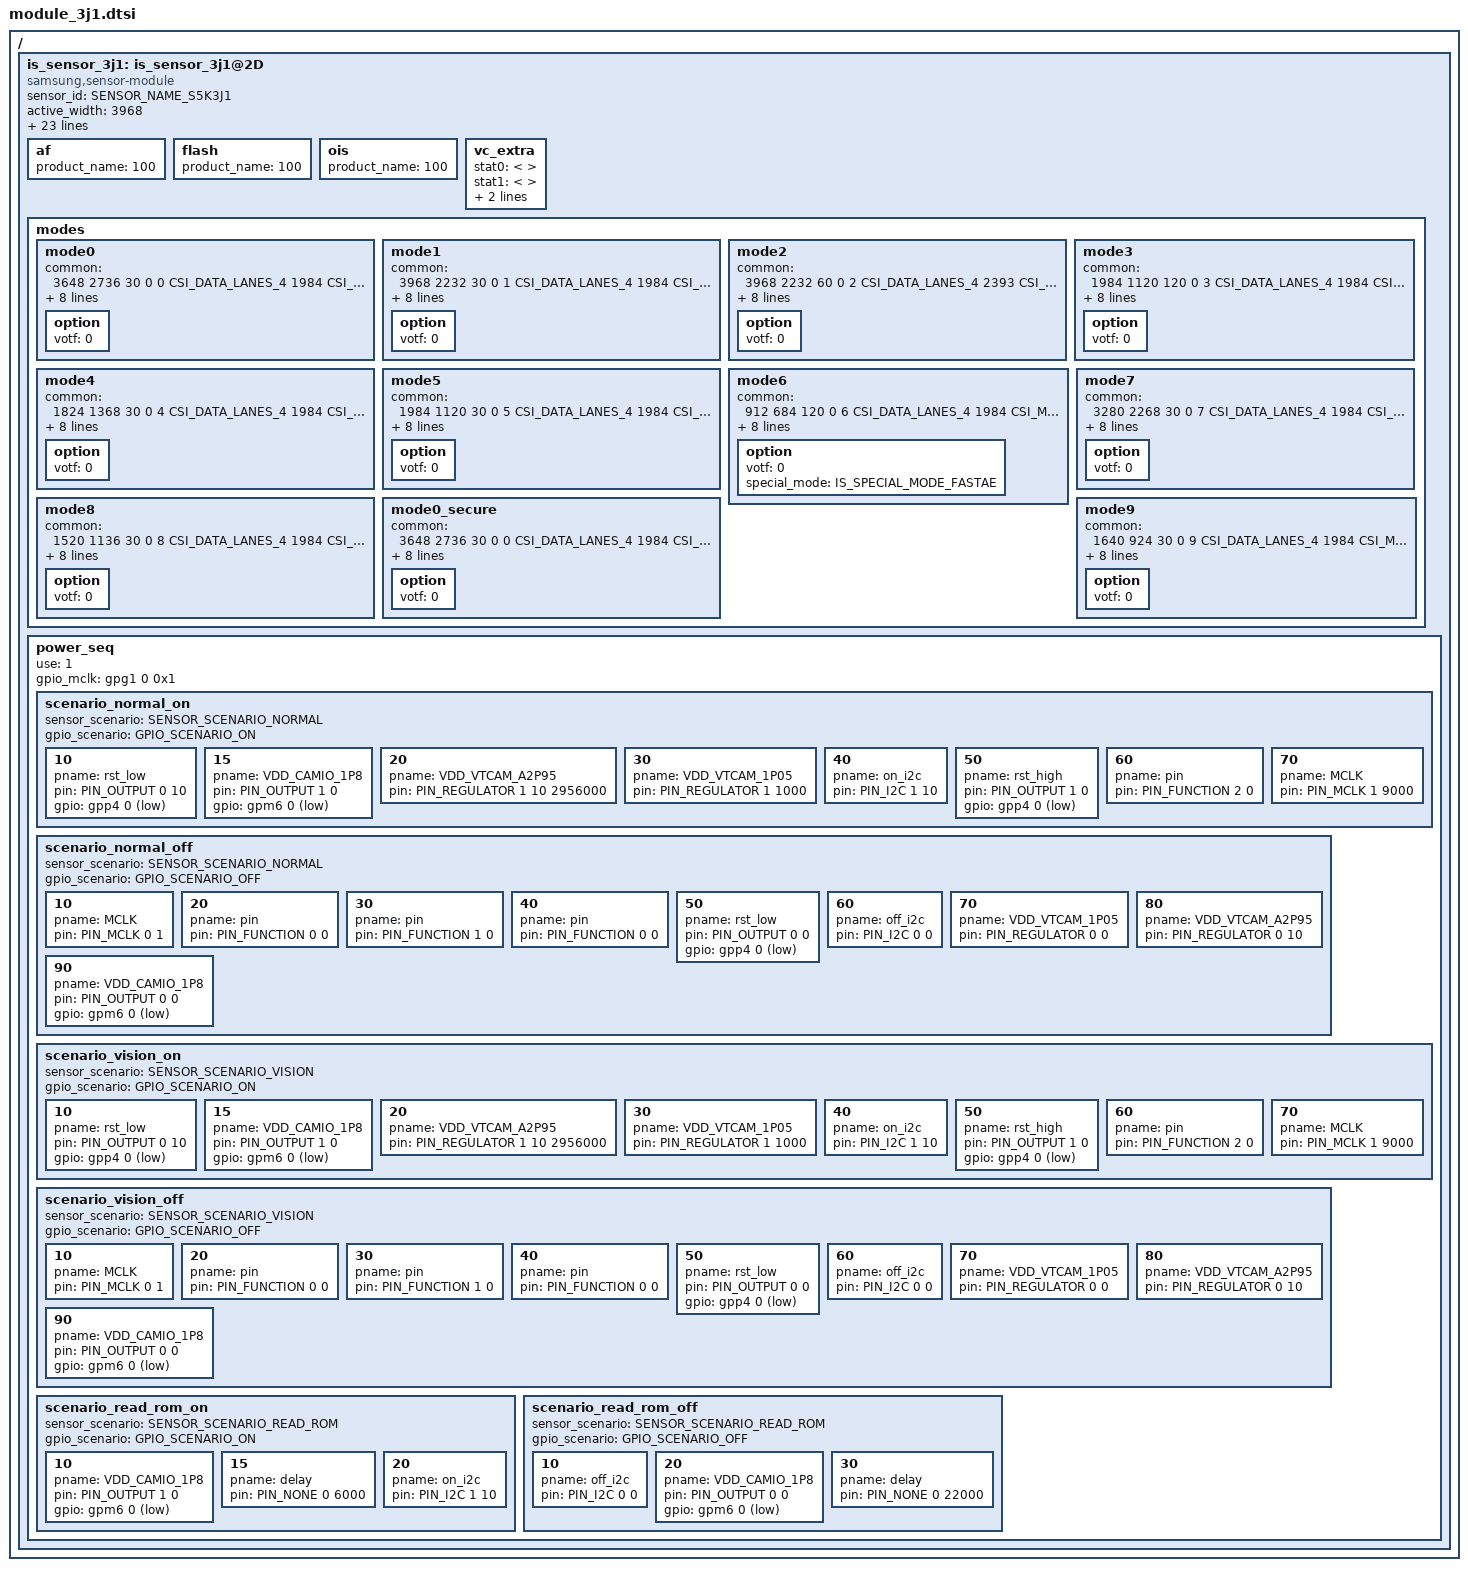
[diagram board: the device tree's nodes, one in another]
/*
 * SAMSUNG EXYNOSxxxx board camera device tree source
 *
 * Copyright (c) 2024 Samsung Electronics Co., Ltd.
 *		http://www.samsung.com
 *
 * This program is free software; you can redistribute it and/or modify
 * it under the terms of the GNU General Public License version 2 as
 * published by the Free Software Foundation.
 */

#include <dt-bindings/camera/exynos_is_dt.h>

/ {
	fragment@camera {
		target-path = "/";
		__overlay__ {
			is_sensor_3j1: is_sensor_3j1@2D {
				compatible = "samsung,sensor-module";

				/* common */
				sensor_id = <SENSOR_NAME_S5K3J1>;
				active_width = <3968>;
				active_height = <2736>;
				margin_left = <0>;
				margin_right = <0>;
				margin_top = <0>;
				margin_bottom = <0>;
				max_framerate = <120>;
				bitwidth = <10>;
				use_retention_mode = <SENSOR_RETENTION_UNSUPPORTED>;
				sensor_maker = "SLSI";
				sensor_name = "S5K3J1";
				setfile_name = "setfile_3j1.bin";

				status = "okay";

				/* board */
				pinctrl-names = "pin0", "pin1", "pin2", "release";
				pinctrl-0 = <>;
				pinctrl-1 = <&sensor_mclk0_out>;
				pinctrl-2 = <&sensor_mclk0_fn>;
				pinctrl-3 = <>;

				position = <1>;	/* Rear:0. Front:1. Rear_sub:2. Secure:3. */
				id = <1>; /* is_sensor id */
				mclk_ch = <0>;
				mclk_freq = <19200>;
				sensor_i2c_ch = <5>; /* SENSOR_CONTROL_I2C5 */

				/* vendor */
				rom_id = <1>;
				rom_cal_index = <0>;

				/* peri*/
				af {
					product_name = <100>; /* NOTHING */
				};

				flash {
					product_name = <100>; /* NOTHING */
				};

				ois {
					product_name = <100>; /* NOTHING */
				};

				vc_extra {
					/* ex) statX = <stat_type, sensor_mode, max_width, max_height, max_element> */
					stat0 = </* not available */>;		/* VC_BUF_DATA_TYPE_SENSOR_STAT1 */
					stat1 = </* not available */>;		/* VC_BUF_DATA_TYPE_GENERAL_STAT1 */
					stat2 = </* not available */>;		/* VC_BUF_DATA_TYPE_SENSOR_STAT2 */
					stat3 = </* not available */>;		/* VC_BUF_DATA_TYPE_GENERAL_STAT2 */
				};

				/* sensor modes */
				modes {
					/* mode0 : 3648x2736@30 (4:3) */
					/* mode1 : 3968x2232@30 (16:9) */
					/* mode2 : 3968x2232@60 (16:9) */
					/* mode3 : 1984x1120@120 2x2 bin (16:9) */
					/* mode4 : 1824x1368@30 2x2 bin (4:3) */
					/* mode5 : 1984x1120@30 2x2 bin (16:9) */
					/* mode6 : 912x684@120 4x4 bin (4:3) */

						/* common = <width, height, fps, settle, mode, lane, speed, interleave, lrte, pd_mode> */
						/* vcX = <map, hwformat, width, height, hwformat, type, width, height> */
					mode0 {
						common = <3648 2736 30 0 0 CSI_DATA_LANES_4 1984 CSI_MODE_VC_ONLY LRTE_DISABLE PD_NONE EX_NONE>;
						vc0 = </* in */ 0 HW_FORMAT_RAW10 DATA_IMG 3648 2736	/* out */ HW_FORMAT_RAW10 VC_NOTHING 3648 2736>;
						vc1 = </* in */ 1 HW_FORMAT_UNKNOWN DATA_NONE 0 0	/* out */ HW_FORMAT_UNKNOWN VC_NOTHING 0 0>;
						vc2 = </* in */ 2 HW_FORMAT_UNKNOWN DATA_NONE 0 0	/* out */ HW_FORMAT_UNKNOWN VC_NOTHING 0 0>;
						vc3 = </* in */ 3 HW_FORMAT_UNKNOWN DATA_NONE 0 0	/* out */ HW_FORMAT_UNKNOWN VC_NOTHING 0 0>;
						option { votf = <0>; };
					};
					mode1 {
						common = <3968 2232 30 0 1 CSI_DATA_LANES_4 1984 CSI_MODE_VC_ONLY LRTE_DISABLE PD_NONE EX_NONE>;
						vc0 = </* in */ 0 HW_FORMAT_RAW10 DATA_IMG 3968 2232	/* out */ HW_FORMAT_RAW10 VC_NOTHING 3968 2232>;
						vc1 = </* in */ 1 HW_FORMAT_UNKNOWN DATA_NONE 0 0	/* out */ HW_FORMAT_UNKNOWN VC_NOTHING 0 0>;
						vc2 = </* in */ 2 HW_FORMAT_UNKNOWN DATA_NONE 0 0	/* out */ HW_FORMAT_UNKNOWN VC_NOTHING 0 0>;
						vc3 = </* in */ 3 HW_FORMAT_UNKNOWN DATA_NONE 0 0	/* out */ HW_FORMAT_UNKNOWN VC_NOTHING 0 0>;
						option { votf = <0>; };
					};
					mode2 {
						common = <3968 2232 60 0 2 CSI_DATA_LANES_4 2393 CSI_MODE_VC_ONLY LRTE_DISABLE PD_NONE EX_NONE>;
						vc0 = </* in */ 0 HW_FORMAT_RAW10 DATA_IMG 3968 2232	/* out */ HW_FORMAT_RAW10 VC_NOTHING 3968 2232>;
						vc1 = </* in */ 1 HW_FORMAT_UNKNOWN DATA_NONE 0 0	/* out */ HW_FORMAT_UNKNOWN VC_NOTHING 0 0>;
						vc2 = </* in */ 2 HW_FORMAT_UNKNOWN DATA_NONE 0 0	/* out */ HW_FORMAT_UNKNOWN VC_NOTHING 0 0>;
						vc3 = </* in */ 3 HW_FORMAT_UNKNOWN DATA_NONE 0 0	/* out */ HW_FORMAT_UNKNOWN VC_NOTHING 0 0>;
						option { votf = <0>; };
					};
					mode3 {
						common = <1984 1120 120 0 3 CSI_DATA_LANES_4 1984 CSI_MODE_VC_ONLY LRTE_DISABLE PD_NONE EX_NONE>;
						vc0 = </* in */ 0 HW_FORMAT_RAW10 DATA_IMG 1984 1120	/* out */ HW_FORMAT_RAW10 VC_NOTHING 1984 1120>;
						vc1 = </* in */ 1 HW_FORMAT_UNKNOWN DATA_NONE 0 0	/* out */ HW_FORMAT_UNKNOWN VC_NOTHING 0 0>;
						vc2 = </* in */ 2 HW_FORMAT_UNKNOWN DATA_NONE 0 0	/* out */ HW_FORMAT_UNKNOWN VC_NOTHING 0 0>;
						vc3 = </* in */ 3 HW_FORMAT_UNKNOWN DATA_NONE 0 0	/* out */ HW_FORMAT_UNKNOWN VC_NOTHING 0 0>;
						option { votf = <0>; };
					};
					mode4 {
						common = <1824 1368 30 0 4 CSI_DATA_LANES_4 1984 CSI_MODE_VC_ONLY LRTE_DISABLE PD_NONE EX_NONE>;
						vc0 = </* in */ 0 HW_FORMAT_RAW10 DATA_IMG 1824 1368	/* out */ HW_FORMAT_RAW10 VC_NOTHING 1824 1368>;
						vc1 = </* in */ 1 HW_FORMAT_UNKNOWN DATA_NONE 0 0	/* out */ HW_FORMAT_UNKNOWN VC_NOTHING 0 0>;
						vc2 = </* in */ 2 HW_FORMAT_UNKNOWN DATA_NONE 0 0	/* out */ HW_FORMAT_UNKNOWN VC_NOTHING 0 0>;
						vc3 = </* in */ 3 HW_FORMAT_UNKNOWN DATA_NONE 0 0	/* out */ HW_FORMAT_UNKNOWN VC_NOTHING 0 0>;
						option { votf = <0>; };
					};
					mode5 {
						common = <1984 1120 30 0 5 CSI_DATA_LANES_4 1984 CSI_MODE_VC_ONLY LRTE_DISABLE PD_NONE EX_NONE>;
						vc0 = </* in */ 0 HW_FORMAT_RAW10 DATA_IMG 1984 1120	/* out */ HW_FORMAT_RAW10 VC_NOTHING 1984 1120>;
						vc1 = </* in */ 1 HW_FORMAT_UNKNOWN DATA_NONE 0 0	/* out */ HW_FORMAT_UNKNOWN VC_NOTHING 0 0>;
						vc2 = </* in */ 2 HW_FORMAT_UNKNOWN DATA_NONE 0 0	/* out */ HW_FORMAT_UNKNOWN VC_NOTHING 0 0>;
						vc3 = </* in */ 3 HW_FORMAT_UNKNOWN DATA_NONE 0 0	/* out */ HW_FORMAT_UNKNOWN VC_NOTHING 0 0>;
						option { votf = <0>; };
					};
					mode6 {
						common = <912 684 120 0 6 CSI_DATA_LANES_4 1984 CSI_MODE_VC_ONLY LRTE_DISABLE PD_NONE EX_NONE>;
						vc0 = </* in */ 0 HW_FORMAT_RAW10 DATA_IMG 912 684	/* out */ HW_FORMAT_RAW10 VC_NOTHING 912 684>;
						vc1 = </* in */ 1 HW_FORMAT_UNKNOWN DATA_NONE 0 0	/* out */ HW_FORMAT_UNKNOWN VC_NOTHING 0 0>;
						vc2 = </* in */ 2 HW_FORMAT_UNKNOWN DATA_NONE 0 0	/* out */ HW_FORMAT_UNKNOWN VC_NOTHING 0 0>;
						vc3 = </* in */ 3 HW_FORMAT_UNKNOWN DATA_NONE 0 0	/* out */ HW_FORMAT_UNKNOWN VC_NOTHING 0 0>;
						option { votf = <0>; special_mode = <IS_SPECIAL_MODE_FASTAE>; };
					};
					mode7 {
						common = <3280 2268 30 0 7 CSI_DATA_LANES_4 1984 CSI_MODE_VC_ONLY LRTE_DISABLE PD_NONE EX_NONE>;
						vc0 = </* in */ 0 HW_FORMAT_RAW10 DATA_IMG 3280 2268	/* out */ HW_FORMAT_RAW10 VC_NOTHING 3280 2268>;
						vc1 = </* in */ 1 HW_FORMAT_UNKNOWN DATA_NONE 0 0	/* out */ HW_FORMAT_UNKNOWN VC_NOTHING 0 0>;
						vc2 = </* in */ 2 HW_FORMAT_UNKNOWN DATA_NONE 0 0	/* out */ HW_FORMAT_UNKNOWN VC_NOTHING 0 0>;
						vc3 = </* in */ 3 HW_FORMAT_UNKNOWN DATA_NONE 0 0	/* out */ HW_FORMAT_UNKNOWN VC_NOTHING 0 0>;
						option { votf = <0>; };
					};
					mode8 {
						common = <1520 1136 30 0 8 CSI_DATA_LANES_4 1984 CSI_MODE_VC_ONLY LRTE_DISABLE PD_NONE EX_NONE>;
						vc0 = </* in */ 0 HW_FORMAT_RAW10 DATA_IMG 1520 1136	/* out */ HW_FORMAT_RAW10 VC_NOTHING 1520 1136>;
						vc1 = </* in */ 1 HW_FORMAT_UNKNOWN DATA_NONE 0 0	/* out */ HW_FORMAT_UNKNOWN VC_NOTHING 0 0>;
						vc2 = </* in */ 2 HW_FORMAT_UNKNOWN DATA_NONE 0 0	/* out */ HW_FORMAT_UNKNOWN VC_NOTHING 0 0>;
						vc3 = </* in */ 3 HW_FORMAT_UNKNOWN DATA_NONE 0 0	/* out */ HW_FORMAT_UNKNOWN VC_NOTHING 0 0>;
						option { votf = <0>; };
					};
					mode9 {
						common = <1640 924 30 0 9 CSI_DATA_LANES_4 1984 CSI_MODE_VC_ONLY LRTE_DISABLE PD_NONE EX_NONE>;
						vc0 = </* in */ 0 HW_FORMAT_RAW10 DATA_IMG 1640 924	/* out */ HW_FORMAT_RAW10 VC_NOTHING 1640 924>;
						vc1 = </* in */ 1 HW_FORMAT_UNKNOWN DATA_NONE 0 0	/* out */ HW_FORMAT_UNKNOWN VC_NOTHING 0 0>;
						vc2 = </* in */ 2 HW_FORMAT_UNKNOWN DATA_NONE 0 0	/* out */ HW_FORMAT_UNKNOWN VC_NOTHING 0 0>;
						vc3 = </* in */ 3 HW_FORMAT_UNKNOWN DATA_NONE 0 0	/* out */ HW_FORMAT_UNKNOWN VC_NOTHING 0 0>;
						option { votf = <0>; };
					};
					/* For SECURE CAMERA FD Scenario */
					mode0_secure {
						common = <3648 2736 30 0 0 CSI_DATA_LANES_4 1984 CSI_MODE_VC_ONLY LRTE_DISABLE PD_NONE EX_PDAF_OFF>;
						vc0 = </* in */ 0 HW_FORMAT_RAW10 DATA_IMG 3648 2736	/* out */ HW_FORMAT_RAW10 VC_NOTHING 1824 1368>;
						vc1 = </* in */ 1 HW_FORMAT_UNKNOWN DATA_NONE 0 0	/* out */ HW_FORMAT_UNKNOWN VC_NOTHING 0 0>;
						vc2 = </* in */ 2 HW_FORMAT_UNKNOWN DATA_NONE 0 0	/* out */ HW_FORMAT_UNKNOWN VC_NOTHING 0 0>;
						vc3 = </* in */ 3 HW_FORMAT_UNKNOWN DATA_NONE 0 0	/* out */ HW_FORMAT_UNKNOWN VC_NOTHING 0 0>;
						option { votf = <0>; };
					};
				};

				power_seq {
					use = <1>;
					gpio_mclk = <&gpg1 0 0x1>;
					scenario_normal_on {
						sensor_scenario = <SENSOR_SCENARIO_NORMAL>;
						gpio_scenario = <GPIO_SCENARIO_ON>;

						/* A start node number should be over the 10 for reserved number 0~9. */
						/* pname = "name"; pin = <act value delay voltage>; gpio = <gpx# # 0x1>; */
						10 { pname = "rst_low"; pin = <PIN_OUTPUT 0 10>; gpio = <&gpp4 0 0x1>; };
						15 { pname = "VDD_CAMIO_1P8"; pin = <PIN_OUTPUT 1 0>; gpio = <&gpm6 0 0x1>; };
						20 { pname = "VDD_VTCAM_A2P95"; pin = <PIN_REGULATOR 1 10 2956000>; };
						30 { pname = "VDD_VTCAM_1P05"; pin = <PIN_REGULATOR 1 1000>; };
						40 { pname = "on_i2c"; pin = <PIN_I2C 1 10>; };
						50 { pname = "rst_high"; pin = <PIN_OUTPUT 1 0>; gpio = <&gpp4 0 0x1>; };
						60 { pname = "pin"; pin = <PIN_FUNCTION 2 0>; };
						70 { pname = "MCLK"; pin = <PIN_MCLK 1 9000>; };
					};

					scenario_normal_off {
						sensor_scenario = <SENSOR_SCENARIO_NORMAL>;
						gpio_scenario = <GPIO_SCENARIO_OFF>;

						/* A start node number should be over the 10 for reserved number 0~9. */
						/* pname = "name"; pin = <act value delay voltage>; gpio = <gpx# # 0x1>; */
						10 { pname = "MCLK"; pin = <PIN_MCLK 0 1>; };
						20 { pname = "pin"; pin = <PIN_FUNCTION 0 0>; };
						30 { pname = "pin"; pin = <PIN_FUNCTION 1 0>; };
						40 { pname = "pin"; pin = <PIN_FUNCTION 0 0>; };
						50 { pname = "rst_low"; pin = <PIN_OUTPUT 0 0>; gpio = <&gpp4 0 0x1>; };
						60 { pname = "off_i2c"; pin = <PIN_I2C 0 0>; };
						70 { pname = "VDD_VTCAM_1P05"; pin = <PIN_REGULATOR 0 0>; };
						80 { pname = "VDD_VTCAM_A2P95"; pin = <PIN_REGULATOR 0 10>; };
						90 { pname = "VDD_CAMIO_1P8"; pin = <PIN_OUTPUT 0 0>; gpio = <&gpm6 0 0x1>; };
					};

					scenario_vision_on {
						sensor_scenario = <SENSOR_SCENARIO_VISION>;
						gpio_scenario = <GPIO_SCENARIO_ON>;

						/* A start node number should be over the 10 for reserved number 0~9. */
						/* pname = "name"; pin = <act value delay voltage>; gpio = <gpx# # 0x1>; */
						10 { pname = "rst_low"; pin = <PIN_OUTPUT 0 10>; gpio = <&gpp4 0 0x1>; };
						15 { pname = "VDD_CAMIO_1P8"; pin = <PIN_OUTPUT 1 0>; gpio = <&gpm6 0 0x1>; };
						20 { pname = "VDD_VTCAM_A2P95"; pin = <PIN_REGULATOR 1 10 2956000>; };
						30 { pname = "VDD_VTCAM_1P05"; pin = <PIN_REGULATOR 1 1000>; };
						40 { pname = "on_i2c"; pin = <PIN_I2C 1 10>; };
						50 { pname = "rst_high"; pin = <PIN_OUTPUT 1 0>; gpio = <&gpp4 0 0x1>; };
						60 { pname = "pin"; pin = <PIN_FUNCTION 2 0>; };
						70 { pname = "MCLK"; pin = <PIN_MCLK 1 9000>; };
					};

					scenario_vision_off {
						sensor_scenario = <SENSOR_SCENARIO_VISION>;
						gpio_scenario = <GPIO_SCENARIO_OFF>;

						/* A start node number should be over the 10 for reserved number 0~9. */
						/* pname = "name"; pin = <act value delay voltage>; gpio = <gpx# # 0x1>; */
						10 { pname = "MCLK"; pin = <PIN_MCLK 0 1>; };
						20 { pname = "pin"; pin = <PIN_FUNCTION 0 0>; };
						30 { pname = "pin"; pin = <PIN_FUNCTION 1 0>; };
						40 { pname = "pin"; pin = <PIN_FUNCTION 0 0>; };
						50 { pname = "rst_low"; pin = <PIN_OUTPUT 0 0>; gpio = <&gpp4 0 0x1>; };
						60 { pname = "off_i2c"; pin = <PIN_I2C 0 0>; };
						70 { pname = "VDD_VTCAM_1P05"; pin = <PIN_REGULATOR 0 0>; };
						80 { pname = "VDD_VTCAM_A2P95"; pin = <PIN_REGULATOR 0 10>; };
						90 { pname = "VDD_CAMIO_1P8"; pin = <PIN_OUTPUT 0 0>; gpio = <&gpm6 0 0x1>; };
					};

					scenario_read_rom_on {
						sensor_scenario = <SENSOR_SCENARIO_READ_ROM>;
						gpio_scenario = <GPIO_SCENARIO_ON>;

						/* A start node number should be over the 10 for reserved number 0~9. */
						/* pname = "name"; pin = <act value delay voltage>; gpio = <gpx# # 0x1>; */
						10 { pname = "VDD_CAMIO_1P8"; pin = <PIN_OUTPUT 1 0>; gpio = <&gpm6 0 0x1>; };
						15 { pname = "delay"; pin = <PIN_NONE 0 6000 >; };
						20 { pname = "on_i2c"; pin = <PIN_I2C 1 10>; };
					};

					scenario_read_rom_off {
						sensor_scenario = <SENSOR_SCENARIO_READ_ROM>;
						gpio_scenario = <GPIO_SCENARIO_OFF>;

						/* A start node number should be over the 10 for reserved number 0~9. */
						/* pname = "name"; pin = <act value delay voltage>; gpio = <gpx# # 0x1>; */
						10 { pname = "off_i2c"; pin = <PIN_I2C 0 0>; };
						20 { pname = "VDD_CAMIO_1P8"; pin = <PIN_OUTPUT 0 0>; gpio = <&gpm6 0 0x1>; };
						30 { pname = "delay"; pin = <PIN_NONE 0 22000>; };
					};
				};
			};
		}; /* end of __overlay__ */
	}; /* end of fragment */
}; /* end of root */
